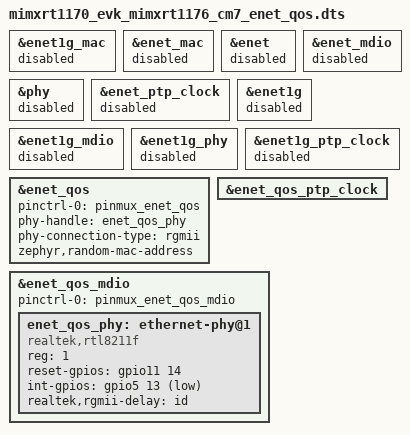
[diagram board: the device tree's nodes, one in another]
/*
 * SPDX-FileCopyrightText: Copyright 2026 NXP
 *
 * SPDX-License-Identifier: Apache-2.0
 */

#include "mimxrt1170_evk_mimxrt1176_cm7.dts"

/*
 * ENET_QOS and ENET_1G share the DISP_B1 RGMII and EMC_B2 MDIO pads and the
 * RTL8211F PHY, so ENET_1G is disabled. ENET (100M) has its own pads and PHY
 * but is disabled as well, so that ENET_QOS is the default interface.
 */

&enet1g_mac {
	status = "disabled";
};

&enet_mac {
	status = "disabled";
};

&enet {
	status = "disabled";
};

&enet_mdio {
	status = "disabled";
};

&phy {
	status = "disabled";
};

&enet_ptp_clock {
	status = "disabled";
};

&enet1g {
	status = "disabled";
};

&enet1g_mdio {
	status = "disabled";
};

&enet1g_phy {
	status = "disabled";
};

&enet1g_ptp_clock {
	status = "disabled";
};

&enet_qos {
	pinctrl-0 = <&pinmux_enet_qos>;
	pinctrl-names = "default";
	phy-handle = <&enet_qos_phy>;
	phy-connection-type = "rgmii";
	zephyr,random-mac-address;
	status = "okay";
};

&enet_qos_ptp_clock {
	status = "okay";
};

&enet_qos_mdio {
	pinctrl-0 = <&pinmux_enet_qos_mdio>;
	pinctrl-names = "default";
	status = "okay";

	enet_qos_phy: ethernet-phy@1 {
		compatible = "realtek,rtl8211f";
		reg = <1>;
		/* Shared with ENET_1G: PHY reset and interrupt lines. */
		reset-gpios = <&gpio11 14 GPIO_ACTIVE_HIGH>;
		int-gpios = <&gpio5 13 GPIO_ACTIVE_LOW>;
		/* The MAC adds no RGMII delay, so the PHY must insert it. */
		realtek,rgmii-delay = "id";
		status = "okay";
	};
};
